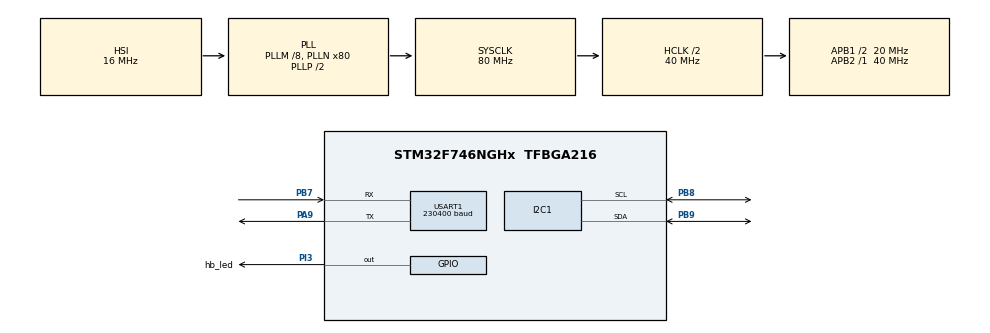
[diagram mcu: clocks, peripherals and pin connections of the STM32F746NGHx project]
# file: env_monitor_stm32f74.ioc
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I2C1.Timing=0x00404C74
Mcu.Family=STM32F7
Mcu.Name=STM32F746NGHx
Mcu.Package=TFBGA216
NVIC.PriorityGroup=NVIC_PRIORITYGROUP_4
NVIC.TIM6_DAC_IRQn=true\:15\:0\:false\:false\:true\:false\:false\:true\:true
NVIC.TimeBase=TIM6_DAC_IRQn
NVIC.TimeBaseIP=TIM6
NVIC.USART1_IRQn=true\:0\:0\:true\:false\:true\:false\:true\:true\:true
PA9.Mode=Asynchronous
PA9.Signal=USART1_TX
PB7.GPIO_PuPd=GPIO_PULLUP
PB7.Mode=Asynchronous
PB7.Signal=USART1_RX
PB8.Mode=I2C
PB8.Signal=I2C1_SCL
PB9.Mode=I2C
PB9.Signal=I2C1_SDA
PI3.GPIO_Label=hb_led
PI3.Signal=GPIO_Output
ProjectManager.HeapSize=0x200
ProjectManager.StackSize=0x400
ProjectManager.TargetToolchain=STM32CubeIDE
RCC.AHBCLKDivider=RCC_SYSCLK_DIV2
RCC.AHBFreq_Value=40000000
RCC.APB1CLKDivider=RCC_HCLK_DIV2
RCC.APB1Freq_Value=20000000
RCC.APB1TimFreq_Value=40000000
RCC.APB2Freq_Value=40000000
RCC.APB2TimFreq_Value=40000000
RCC.CortexFreq_Value=40000000
RCC.HCLKFreq_Value=40000000
RCC.HSE_VALUE=25000000
RCC.HSI_VALUE=16000000
RCC.LSE_VALUE=32768
RCC.PLLM=8
RCC.PLLN=80
RCC.SYSCLKFreq_VALUE=80000000
RCC.SYSCLKSource=RCC_SYSCLKSOURCE_PLLCLK
RCC.USBFreq_Value=80000000
RCC.VCOOutputFreq_Value=160000000
STMicroelectronics.X-CUBE-AZRTOS-F7.1.0.0.ThreadXCcRTOSJjThreadXJjCore=true
STMicroelectronics.X-CUBE-AZRTOS-F7.1.0.0_IsAnAzureRtosMw=true
USART1.BaudRate=230400
USART1.VirtualMode-Asynchronous=VM_ASYNC
VP_STMicroelectronics.X-CUBE-AZRTOS-F7_VS_RTOSJjThreadX_6.1.8_1.0.0.Mode=RTOSJjThreadX
VP_SYS_VS_tim6.Mode=TIM6
board=custom

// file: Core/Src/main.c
/* USER CODE BEGIN Header */
/**
  ******************************************************************************
  * @file           : main.c
  * @brief          : Main program body
  ******************************************************************************
  * @attention
  *
  * Copyright (c) 2022 STMicroelectronics.
  * All rights reserved.
  *
  * This software is licensed under terms that can be found in the LICENSE file
  * in the root directory of this software component.
  * If no LICENSE file comes with this software, it is provided AS-IS.
  *
  ******************************************************************************
  */
/* USER CODE END Header */
#include "main.h"
#include "app_threadx.h"

/* USER CODE BEGIN Includes */
#include "../EnvCore/serialcom/serialcom.h"

/* USER CODE END Includes */

I2C_HandleTypeDef hi2c1;

UART_HandleTypeDef huart1;

void SystemClock_Config(void);
static void MX_GPIO_Init(void);
static void MX_I2C1_Init(void);
static void MX_USART1_UART_Init(void);

/* USER CODE BEGIN 0 */

//Set external variables
 UART_HandleTypeDef *UART_DRV = &huart1;

/* USER CODE END 0 */

int main(void)
{

  /* MCU Configuration--------------------------------------------------------*/

  /* Reset of all peripherals, Initializes the Flash interface and the Systick. */
  HAL_Init();

  /* Configure the system clock */
  SystemClock_Config();

  /* Initialize all configured peripherals */
  MX_GPIO_Init();
  MX_I2C1_Init();
  MX_USART1_UART_Init();
  /* USER CODE BEGIN 2 */

  serial_print("\n--- Starting Env Monitor ---\n\r");
  serial_print("Version: 0.1\n\n\r");
  HAL_Delay(200);

  /* USER CODE END 2 */

  MX_ThreadX_Init();

  /* We should never get here as control is now taken by the scheduler */
  /* Infinite loop */
  while (1)
  {

  }
}

void SystemClock_Config(void)
{
  RCC_OscInitTypeDef RCC_OscInitStruct = {0};
  RCC_ClkInitTypeDef RCC_ClkInitStruct = {0};

  /** Configure the main internal regulator output voltage
  */
  __HAL_RCC_PWR_CLK_ENABLE();
  __HAL_PWR_VOLTAGESCALING_CONFIG(PWR_REGULATOR_VOLTAGE_SCALE3);

  /** Initializes the RCC Oscillators according to the specified parameters
  * in the RCC_OscInitTypeDef structure.
  */
  RCC_OscInitStruct.OscillatorType = RCC_OSCILLATORTYPE_HSI;
  RCC_OscInitStruct.HSIState = RCC_HSI_ON;
  RCC_OscInitStruct.HSICalibrationValue = RCC_HSICALIBRATION_DEFAULT;
  RCC_OscInitStruct.PLL.PLLState = RCC_PLL_ON;
  RCC_OscInitStruct.PLL.PLLSource = RCC_PLLSOURCE_HSI;
  RCC_OscInitStruct.PLL.PLLM = 8;
  RCC_OscInitStruct.PLL.PLLN = 80;
  RCC_OscInitStruct.PLL.PLLP = RCC_PLLP_DIV2;
  RCC_OscInitStruct.PLL.PLLQ = 2;
  if (HAL_RCC_OscConfig(&RCC_OscInitStruct) != HAL_OK)
  {
    Error_Handler();
  }

  /** Initializes the CPU, AHB and APB buses clocks
  */
  RCC_ClkInitStruct.ClockType = RCC_CLOCKTYPE_HCLK|RCC_CLOCKTYPE_SYSCLK
                              |RCC_CLOCKTYPE_PCLK1|RCC_CLOCKTYPE_PCLK2;
  RCC_ClkInitStruct.SYSCLKSource = RCC_SYSCLKSOURCE_PLLCLK;
  RCC_ClkInitStruct.AHBCLKDivider = RCC_SYSCLK_DIV2;
  RCC_ClkInitStruct.APB1CLKDivider = RCC_HCLK_DIV2;
  RCC_ClkInitStruct.APB2CLKDivider = RCC_HCLK_DIV1;

  if (HAL_RCC_ClockConfig(&RCC_ClkInitStruct, FLASH_LATENCY_1) != HAL_OK)
  {
    Error_Handler();
  }
}

static void MX_I2C1_Init(void)
{

  hi2c1.Instance = I2C1;
  hi2c1.Init.Timing = 0x00404C74;
  hi2c1.Init.OwnAddress1 = 0;
  hi2c1.Init.AddressingMode = I2C_ADDRESSINGMODE_7BIT;
  hi2c1.Init.DualAddressMode = I2C_DUALADDRESS_DISABLE;
  hi2c1.Init.OwnAddress2 = 0;
  hi2c1.Init.OwnAddress2Masks = I2C_OA2_NOMASK;
  hi2c1.Init.GeneralCallMode = I2C_GENERALCALL_DISABLE;
  hi2c1.Init.NoStretchMode = I2C_NOSTRETCH_DISABLE;
  if (HAL_I2C_Init(&hi2c1) != HAL_OK)
  {
    Error_Handler();
  }

  /** Configure Analogue filter
  */
  if (HAL_I2CEx_ConfigAnalogFilter(&hi2c1, I2C_ANALOGFILTER_ENABLE) != HAL_OK)
  {
    Error_Handler();
  }

  /** Configure Digital filter
  */
  if (HAL_I2CEx_ConfigDigitalFilter(&hi2c1, 0) != HAL_OK)
  {
    Error_Handler();
  }

}

static void MX_USART1_UART_Init(void)
{

  huart1.Instance = USART1;
  huart1.Init.BaudRate = 230400;
  huart1.Init.WordLength = UART_WORDLENGTH_8B;
  huart1.Init.StopBits = UART_STOPBITS_1;
  huart1.Init.Parity = UART_PARITY_NONE;
  huart1.Init.Mode = UART_MODE_TX_RX;
  huart1.Init.HwFlowCtl = UART_HWCONTROL_NONE;
  huart1.Init.OverSampling = UART_OVERSAMPLING_16;
  huart1.Init.OneBitSampling = UART_ONE_BIT_SAMPLE_DISABLE;
  huart1.AdvancedInit.AdvFeatureInit = UART_ADVFEATURE_NO_INIT;
  if (HAL_UART_Init(&huart1) != HAL_OK)
  {
    Error_Handler();
  }
  /* USER CODE BEGIN USART1_Init 2 */

  USART1->CR1 |= USART_CR1_RXNEIE;      //Enable uart RX interrupt
  //USART1->CR1 |= USART_CR1_IDLEIE;    //Idle interrupt

  /* USER CODE END USART1_Init 2 */

}

static void MX_GPIO_Init(void)
{
  GPIO_InitTypeDef GPIO_InitStruct = {0};

  /* GPIO Ports Clock Enable */
  __HAL_RCC_GPIOB_CLK_ENABLE();
  __HAL_RCC_GPIOI_CLK_ENABLE();
  __HAL_RCC_GPIOA_CLK_ENABLE();

  /*Configure GPIO pin Output Level */
  HAL_GPIO_WritePin(hb_led_GPIO_Port, hb_led_Pin, GPIO_PIN_RESET);

  /*Configure GPIO pin : hb_led_Pin */
  GPIO_InitStruct.Pin = hb_led_Pin;
  GPIO_InitStruct.Mode = GPIO_MODE_OUTPUT_PP;
  GPIO_InitStruct.Pull = GPIO_NOPULL;
  GPIO_InitStruct.Speed = GPIO_SPEED_FREQ_LOW;
  HAL_GPIO_Init(hb_led_GPIO_Port, &GPIO_InitStruct);

}

void HAL_TIM_PeriodElapsedCallback(TIM_HandleTypeDef *htim)
{
  if (htim->Instance == TIM6) {
    HAL_IncTick();
  }
}

void Error_Handler(void)
{
  __disable_irq();
  while (1)
  {
  }
}
